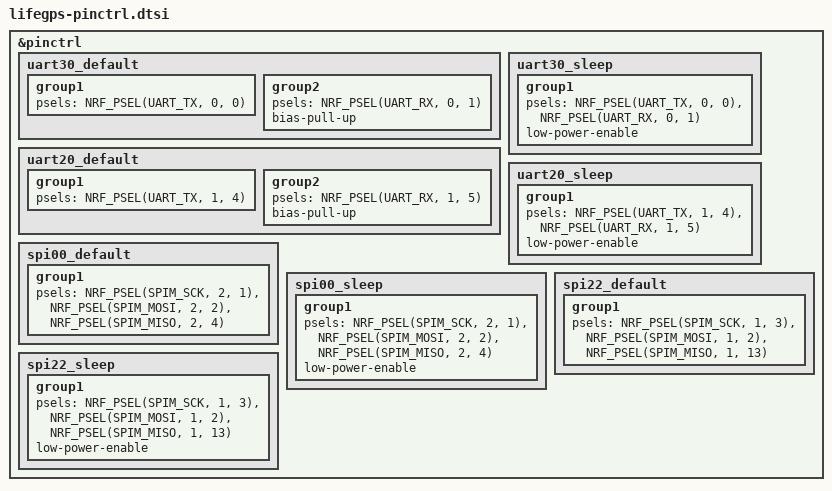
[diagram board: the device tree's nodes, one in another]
/*
 * Copyright (c) 2026 Life_GPS contributors
 * SPDX-License-Identifier: MIT
 *
 * Pin assignments for Main_V0.2. Every PSEL below quotes the pinmap SSOT
 * Doc/Hardware/Pinmap_Main_V0.2.md section 2 (nRF54L15-QFAA, QFN48):
 *
 *   DEBUG_TX  P0.00 (pin 23)  DEBUG_RX  P0.01 (pin 24)   -> UARTE30 (LP domain)
 *   GPS_TX    P1.04 (pin  5)  GPS_RX    P1.05 (pin  6)   -> UARTE20 (PERI domain)
 *   SPI_CLK   P2.01 (pin 12)  SPI_MOSI  P2.02 (pin 13)   -> SPIM00 (MCU domain)
 *   SPI_MISO  P2.04 (pin 15)  SPI_CS    P2.05 (pin 16)
 *   LSM6 SCK  P1.03 (pin  4)  LSM6 MOSI P1.02 (pin  3)   -> SPIM22 (PERI domain)
 *   LSM6 MISO P1.13 (pin 41)  LSM6 CS   P1.14 (pin 42)
 *
 * P1.02 / P1.03 are the NFC antenna pads after reset; the board enables
 * "nfct-pins-as-gpios" in &uicr so they work as SPIM22 pins.
 */

&pinctrl {
	/omit-if-no-ref/ uart30_default: uart30_default {
		group1 {
			psels = <NRF_PSEL(UART_TX, 0, 0)>;
		};

		group2 {
			psels = <NRF_PSEL(UART_RX, 0, 1)>;
			bias-pull-up;
		};
	};

	/omit-if-no-ref/ uart30_sleep: uart30_sleep {
		group1 {
			psels = <NRF_PSEL(UART_TX, 0, 0)>,
				<NRF_PSEL(UART_RX, 0, 1)>;
			low-power-enable;
		};
	};

	/omit-if-no-ref/ uart20_default: uart20_default {
		group1 {
			psels = <NRF_PSEL(UART_TX, 1, 4)>;
		};

		group2 {
			psels = <NRF_PSEL(UART_RX, 1, 5)>;
			bias-pull-up;
		};
	};

	/omit-if-no-ref/ uart20_sleep: uart20_sleep {
		group1 {
			psels = <NRF_PSEL(UART_TX, 1, 4)>,
				<NRF_PSEL(UART_RX, 1, 5)>;
			low-power-enable;
		};
	};

	/omit-if-no-ref/ spi00_default: spi00_default {
		group1 {
			psels = <NRF_PSEL(SPIM_SCK, 2, 1)>,
				<NRF_PSEL(SPIM_MOSI, 2, 2)>,
				<NRF_PSEL(SPIM_MISO, 2, 4)>;
		};
	};

	/omit-if-no-ref/ spi00_sleep: spi00_sleep {
		group1 {
			psels = <NRF_PSEL(SPIM_SCK, 2, 1)>,
				<NRF_PSEL(SPIM_MOSI, 2, 2)>,
				<NRF_PSEL(SPIM_MISO, 2, 4)>;
			low-power-enable;
		};
	};

	/omit-if-no-ref/ spi22_default: spi22_default {
		group1 {
			psels = <NRF_PSEL(SPIM_SCK, 1, 3)>,
				<NRF_PSEL(SPIM_MOSI, 1, 2)>,
				<NRF_PSEL(SPIM_MISO, 1, 13)>;
		};
	};

	/omit-if-no-ref/ spi22_sleep: spi22_sleep {
		group1 {
			psels = <NRF_PSEL(SPIM_SCK, 1, 3)>,
				<NRF_PSEL(SPIM_MOSI, 1, 2)>,
				<NRF_PSEL(SPIM_MISO, 1, 13)>;
			low-power-enable;
		};
	};
};
